VERSION ""

NS_ :

BS_:

BU_: VCU BMS EPAS GPS HVAC

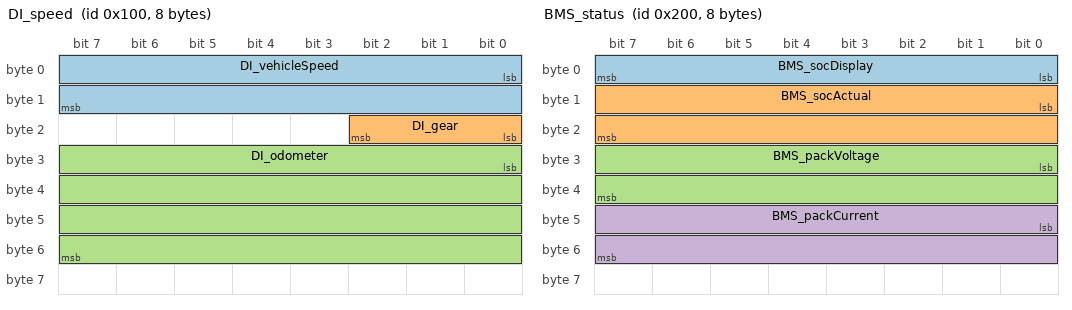
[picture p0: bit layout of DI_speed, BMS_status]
BO_ 256 DI_speed: 8 VCU
 SG_ DI_vehicleSpeed : 0|16@1+ (0.1,0) [0|655.35] "km/h" Vector__XXX
 SG_ DI_gear : 16|3@1+ (1,0) [0|7] "" Vector__XXX
 SG_ DI_odometer : 24|32@1+ (0.1,0) [0|429496729.5] "km" Vector__XXX

BO_ 512 BMS_status: 8 BMS
 SG_ BMS_socDisplay : 0|8@1+ (0.5,0) [0|100] "%" Vector__XXX
 SG_ BMS_socActual : 8|16@1+ (0.01,0) [0|100] "%" Vector__XXX
 SG_ BMS_packVoltage : 24|16@1+ (0.1,0) [0|800] "V" Vector__XXX
 SG_ BMS_packCurrent : 40|16@1- (0.1,0) [-500|500] "A" Vector__XXX

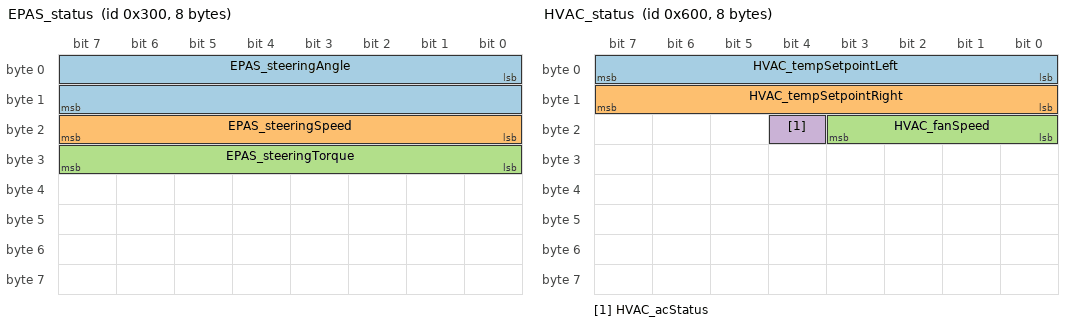
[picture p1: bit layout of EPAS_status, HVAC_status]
BO_ 768 EPAS_status: 8 EPAS
 SG_ EPAS_steeringAngle : 0|16@1- (0.1,0) [-600|600] "deg" Vector__XXX
 SG_ EPAS_steeringSpeed : 16|8@1+ (4,0) [0|1016] "deg/s" Vector__XXX
 SG_ EPAS_steeringTorque : 24|8@1- (0.5,0) [-64|63.5] "Nm" Vector__XXX

BO_ 1024 GPS_position: 8 GPS
 SG_ GPS_latitude : 0|32@1- (0.0000001,0) [-90|90] "deg" Vector__XXX
 SG_ GPS_longitude : 32|32@1- (0.0000001,0) [-180|180] "deg" Vector__XXX

BO_ 1280 VCLEFT_status: 4 VCU
 SG_ VCLEFT_turnSignalStatus : 0|2@1+ (1,0) [0|3] "" Vector__XXX
 SG_ VCLEFT_hazardStatus : 2|1@1+ (1,0) [0|1] "" Vector__XXX

BO_ 1281 VCRIGHT_status: 4 VCU
 SG_ VCRIGHT_turnSignalStatus : 0|2@1+ (1,0) [0|3] "" Vector__XXX

BO_ 1536 HVAC_status: 8 HVAC
 SG_ HVAC_tempSetpointLeft : 0|8@1+ (0.5,15) [15|30] "C" Vector__XXX
 SG_ HVAC_tempSetpointRight : 8|8@1+ (0.5,15) [15|30] "C" Vector__XXX
 SG_ HVAC_fanSpeed : 16|4@1+ (1,0) [0|10] "" Vector__XXX
 SG_ HVAC_acStatus : 20|1@1+ (1,0) [0|1] "" Vector__XXX

CM_ BU_ VCU "Vehicle Control Unit";
CM_ BU_ BMS "Battery Management System";
CM_ BU_ EPAS "Electric Power Assisted Steering";
CM_ BU_ GPS "GPS Receiver";
CM_ BU_ HVAC "Heating Ventilation Air Conditioning";

CM_ BO_ 256 "Drive inverter / vehicle speed message";
CM_ BO_ 512 "Battery management system status";
CM_ BO_ 768 "Steering status";
CM_ BO_ 1024 "GPS position";
CM_ BO_ 1280 "Left side body controller";
CM_ BO_ 1281 "Right side body controller";
CM_ BO_ 1536 "HVAC status";

CM_ SG_ 256 DI_vehicleSpeed "Vehicle speed in km/h";
CM_ SG_ 256 DI_gear "Gear position: 0=R, 1=P/N, 2=D, 3=L";
CM_ SG_ 512 BMS_socDisplay "Displayed state of charge";
CM_ SG_ 512 BMS_packCurrent "Pack current, positive=discharge";
CM_ SG_ 768 EPAS_steeringAngle "Steering wheel angle, left=positive";

VAL_ 256 DI_gear 0 "Reverse" 1 "Park" 2 "Drive" 3 "Low" ;
VAL_ 1280 VCLEFT_turnSignalStatus 0 "Off" 1 "On" 2 "Blinking" ;
VAL_ 1281 VCRIGHT_turnSignalStatus 0 "Off" 1 "On" 2 "Blinking" ;
